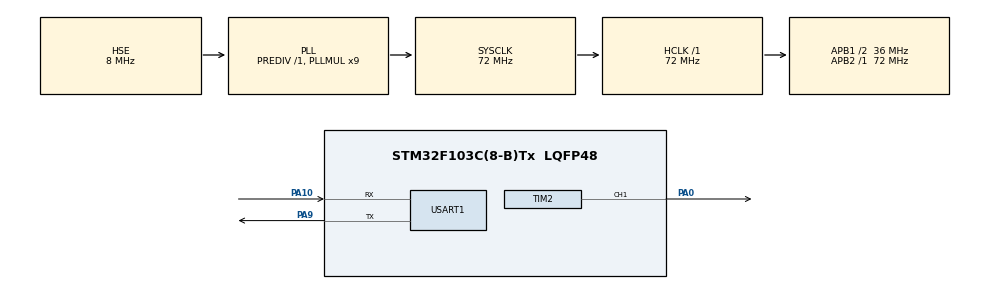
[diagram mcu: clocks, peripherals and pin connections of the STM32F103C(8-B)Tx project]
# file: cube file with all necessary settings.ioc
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Dma.Request0=TIM2_CH1
Dma.TIM2_CH1.0.Direction=DMA_MEMORY_TO_PERIPH
Dma.TIM2_CH1.0.Instance=DMA1_Channel5
Dma.TIM2_CH1.0.MemDataAlignment=DMA_MDATAALIGN_BYTE
Dma.TIM2_CH1.0.MemInc=DMA_MINC_ENABLE
Dma.TIM2_CH1.0.Mode=DMA_CIRCULAR
Dma.TIM2_CH1.0.PeriphDataAlignment=DMA_PDATAALIGN_WORD
Dma.TIM2_CH1.0.PeriphInc=DMA_PINC_DISABLE
Dma.TIM2_CH1.0.Priority=DMA_PRIORITY_HIGH
Mcu.Family=STM32F1
Mcu.Name=STM32F103C(8-B)Tx
Mcu.Package=LQFP48
NVIC.DMA1_Channel5_IRQn=true\:0\:0\:false\:false\:true\:false
NVIC.PriorityGroup=NVIC_PRIORITYGROUP_4
NVIC.TIM2_IRQn=true\:0\:0\:false\:false\:true\:true
PA0-WKUP.GPIO_Speed=GPIO_SPEED_FREQ_HIGH
PA0-WKUP.Signal=S_TIM2_CH1_ETR
PA10.Mode=Asynchronous
PA10.Signal=USART1_RX
PA13.Mode=Serial_Wire
PA13.Signal=SYS_JTMS-SWDIO
PA14.Mode=Serial_Wire
PA14.Signal=SYS_JTCK-SWCLK
PA9.Mode=Asynchronous
PA9.Signal=USART1_TX
PD0-OSC_IN.Mode=HSE-External-Oscillator
PD0-OSC_IN.Signal=RCC_OSC_IN
PD1-OSC_OUT.Mode=HSE-External-Oscillator
PD1-OSC_OUT.Signal=RCC_OSC_OUT
ProjectManager.HeapSize=0x200
ProjectManager.StackSize=0x400
ProjectManager.TargetToolchain=MDK-ARM V5
RCC.AHBFreq_Value=72000000
RCC.APB1CLKDivider=RCC_HCLK_DIV2
RCC.APB1Freq_Value=36000000
RCC.APB1TimFreq_Value=72000000
RCC.APB2Freq_Value=72000000
RCC.APB2TimFreq_Value=72000000
RCC.HCLKFreq_Value=72000000
RCC.PLLMUL=RCC_PLL_MUL9
RCC.PLLSourceVirtual=RCC_PLLSOURCE_HSE
RCC.SYSCLKFreq_VALUE=72000000
RCC.SYSCLKSource=RCC_SYSCLKSOURCE_PLLCLK
RCC.USBFreq_Value=72000000
SH.S_TIM2_CH1_ETR.0=TIM2_CH1,PWM Generation1 CH1
TIM2.AutoReloadPreload=TIM_AUTORELOAD_PRELOAD_DISABLE
TIM2.Channel-PWM\ Generation1\ CH1=TIM_CHANNEL_1
TIM2.Period=0
TIM2.Prescaler=0
TIM2.Pulse-PWM\ Generation1\ CH1=0
USART1.VirtualMode=VM_ASYNC
VP_TIM2_VS_ClockSourceINT.Mode=Internal
board=custom

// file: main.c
/**
  ******************************************************************************
  * @file           : main.c
  * @brief          : Main program body
  ******************************************************************************
  ** This notice applies to any and all portions of this file
  * that are not between comment pairs USER CODE BEGIN and
  * USER CODE END. Other portions of this file, whether
  * inserted by the user or by software development tools
  * are owned by their respective copyright owners.
  *
  * COPYRIGHT(c) 2019 STMicroelectronics
  *
  * Redistribution and use in source and binary forms, with or without modification,
  * are permitted provided that the following conditions are met:
  *   1. Redistributions of source code must retain the above copyright notice,
  *      this list of conditions and the following disclaimer.
  *   2. Redistributions in binary form must reproduce the above copyright notice,
  *      this list of conditions and the following disclaimer in the documentation
  *      and/or other materials provided with the distribution.
  *   3. Neither the name of STMicroelectronics nor the names of its contributors
  *      may be used to endorse or promote products derived from this software
  *      without specific prior written permission.
  *
  * THIS SOFTWARE IS PROVIDED BY THE COPYRIGHT HOLDERS AND CONTRIBUTORS "AS IS"
  * AND ANY EXPRESS OR IMPLIED WARRANTIES, INCLUDING, BUT NOT LIMITED TO, THE
  * IMPLIED WARRANTIES OF MERCHANTABILITY AND FITNESS FOR A PARTICULAR PURPOSE ARE
  * DISCLAIMED. IN NO EVENT SHALL THE COPYRIGHT HOLDER OR CONTRIBUTORS BE LIABLE
  * FOR ANY DIRECT, INDIRECT, INCIDENTAL, SPECIAL, EXEMPLARY, OR CONSEQUENTIAL
  * DAMAGES (INCLUDING, BUT NOT LIMITED TO, PROCUREMENT OF SUBSTITUTE GOODS OR
  * SERVICES; LOSS OF USE, DATA, OR PROFITS; OR BUSINESS INTERRUPTION) HOWEVER
  * CAUSED AND ON ANY THEORY OF LIABILITY, WHETHER IN CONTRACT, STRICT LIABILITY,
  * OR TORT (INCLUDING NEGLIGENCE OR OTHERWISE) ARISING IN ANY WAY OUT OF THE USE
  * OF THIS SOFTWARE, EVEN IF ADVISED OF THE POSSIBILITY OF SUCH DAMAGE.
  *
  ******************************************************************************
  */
#include "main.h"
#include "stm32f1xx_hal.h"

TIM_HandleTypeDef htim2;
DMA_HandleTypeDef hdma_tim2_ch1;
UART_HandleTypeDef huart1;

/* USER CODE BEGIN PV */
/* Private variables ---------------------------------------------------------*/

#include "RGB_library.h"

/* USER CODE END PV */

void SystemClock_Config(void);
static void MX_GPIO_Init(void);
static void MX_DMA_Init(void);
static void MX_TIM2_Init(void);
static void MX_USART1_UART_Init(void);
void HAL_TIM_MspPostInit(TIM_HandleTypeDef *htim);

/* USER CODE BEGIN PFP */
/* Private function prototypes -----------------------------------------------*/

/* USER CODE END PFP */

/* USER CODE BEGIN 0 */

#define WS2812_FREQ											(800000) 			// WS2812 require 800kHz frequency
#define TIMER_CLOCK_FREQ								(72000000)   	// it is depend on APB clk-bus
#define TIMER_PERIOD										(TIMER_CLOCK_FREQ / WS2812_FREQ)
#define LED_NUMBER											3						// number of LEDs we must control
#define LED_DATA_SIZE										(LED_NUMBER * 24)
#define RESET_SLOTS_BEGIN								50	//code reset time
#define RESET_SLOTS_END									50	//code reset time
#define WS2812_LAST_SLOT								1		//set one bit for end of sending pulse
#define LED_BUFFER_SIZE									(RESET_SLOTS_BEGIN + LED_DATA_SIZE + WS2812_LAST_SLOT + RESET_SLOTS_END)
#define WS2812_0											  (TIMER_PERIOD / 3)			// WS2812's zero => high time is one third of the period
#define WS2812_1											  (TIMER_PERIOD * 2 / 3)	// WS2812's one => high time is two thirds of the period
#define WS2812_RESET										 0

/* USER CODE END 0 */

int main(void)
{

  /* MCU Configuration----------------------------------------------------------*/

  /* Reset of all peripherals, Initializes the Flash interface and the Systick. */
  HAL_Init();

  /* Configure the system clock */
  SystemClock_Config();

  /* Initialize all configured peripherals */

	MX_GPIO_Init();
  MX_DMA_Init();
  MX_TIM2_Init();
  MX_USART1_UART_Init();

  /* USER CODE BEGIN 2 */

//	uint32_t pdata[73]={60,60,60,60,60,60,60,60,30,30,30,30,30,30,30,30,30,30,30,30,30,30,30,30,
//						30,30,30,30,30,30,30,30,60,60,60,60,60,60,60,60,30,30,30,30,30,30,30,30,
//						30,30,30,30,30,30,30,30,30,30,30,30,30,30,30,30,60,60,60,60,60,60,60,60,0};

//	HAL_TIM_PWM_Start_DMA(&htim2,TIM_CHANNEL_1,(uint32_t *)pdata,73);

//	HAL_UART_Transmit(&huart1,(uint8_t *)LEDbuffer,LED_BUFFER_SIZE,100);

//	setLEDcolor(0,0x01,0x11,0xf0);
//	setLEDcolor(1,0x00,0xff,0xff);
//	setLEDcolor(2,0x00,0x00,0xff);

	setWHOLEcolor(0xff,0x00,0x00);

	HAL_UART_Transmit(&huart1,(uint8_t *)LEDbuffer,LED_BUFFER_SIZE,100);
  HAL_TIM_PWM_Start_DMA(&htim2, TIM_CHANNEL_1, (uint32_t *) LEDbuffer,LED_BUFFER_SIZE);

  /* USER CODE END 2 */

  /* Infinite loop */
  while (1)
  {

	}

}

void SystemClock_Config(void)
{

  RCC_OscInitTypeDef RCC_OscInitStruct;
  RCC_ClkInitTypeDef RCC_ClkInitStruct;

    /**Initializes the CPU, AHB and APB busses clocks
    */
  RCC_OscInitStruct.OscillatorType = RCC_OSCILLATORTYPE_HSE;
  RCC_OscInitStruct.HSEState = RCC_HSE_ON;
  RCC_OscInitStruct.HSEPredivValue = RCC_HSE_PREDIV_DIV1;
  RCC_OscInitStruct.HSIState = RCC_HSI_ON;
  RCC_OscInitStruct.PLL.PLLState = RCC_PLL_ON;
  RCC_OscInitStruct.PLL.PLLSource = RCC_PLLSOURCE_HSE;
  RCC_OscInitStruct.PLL.PLLMUL = RCC_PLL_MUL9;
  if (HAL_RCC_OscConfig(&RCC_OscInitStruct) != HAL_OK)
  {
    _Error_Handler(__FILE__, __LINE__);
  }

    /**Initializes the CPU, AHB and APB busses clocks
    */
  RCC_ClkInitStruct.ClockType = RCC_CLOCKTYPE_HCLK|RCC_CLOCKTYPE_SYSCLK
                              |RCC_CLOCKTYPE_PCLK1|RCC_CLOCKTYPE_PCLK2;
  RCC_ClkInitStruct.SYSCLKSource = RCC_SYSCLKSOURCE_PLLCLK;
  RCC_ClkInitStruct.AHBCLKDivider = RCC_SYSCLK_DIV1;
  RCC_ClkInitStruct.APB1CLKDivider = RCC_HCLK_DIV2;
  RCC_ClkInitStruct.APB2CLKDivider = RCC_HCLK_DIV1;

  if (HAL_RCC_ClockConfig(&RCC_ClkInitStruct, FLASH_LATENCY_2) != HAL_OK)
  {
    _Error_Handler(__FILE__, __LINE__);
  }

    /**Configure the Systick interrupt time
    */
  HAL_SYSTICK_Config(HAL_RCC_GetHCLKFreq()/1000);

    /**Configure the Systick
    */
  HAL_SYSTICK_CLKSourceConfig(SYSTICK_CLKSOURCE_HCLK);

  /* SysTick_IRQn interrupt configuration */
  HAL_NVIC_SetPriority(SysTick_IRQn, 0, 0);
}

/* TIM2 init function */
static void MX_TIM2_Init(void)
{

  TIM_ClockConfigTypeDef sClockSourceConfig;
  TIM_MasterConfigTypeDef sMasterConfig;
  TIM_OC_InitTypeDef sConfigOC;

  htim2.Instance = TIMx;
  htim2.Init.Prescaler = (uint32_t)((SystemCoreClock / TIMER_CLOCK_FREQ) - 1);
  htim2.Init.CounterMode = TIM_COUNTERMODE_UP;
  htim2.Init.Period = TIMER_PERIOD - 1;
  htim2.Init.ClockDivision = TIM_CLOCKDIVISION_DIV1;
	htim2.Init.RepetitionCounter = LED_BUFFER_SIZE + 1;
	htim2.Init.AutoReloadPreload = TIM_AUTORELOAD_PRELOAD_DISABLE;
  if (HAL_TIM_Base_Init(&htim2) != HAL_OK)
  {
    _Error_Handler(__FILE__, __LINE__);
  }

  sClockSourceConfig.ClockSource = TIM_CLOCKSOURCE_INTERNAL;
  if (HAL_TIM_ConfigClockSource(&htim2, &sClockSourceConfig) != HAL_OK)
  {
    _Error_Handler(__FILE__, __LINE__);
  }

  if (HAL_TIM_PWM_Init(&htim2) != HAL_OK)
  {
    _Error_Handler(__FILE__, __LINE__);
  }

  sMasterConfig.MasterOutputTrigger = TIM_TRGO_RESET;
  sMasterConfig.MasterSlaveMode = TIM_MASTERSLAVEMODE_DISABLE;
  if (HAL_TIMEx_MasterConfigSynchronization(&htim2, &sMasterConfig) != HAL_OK)
  {
    _Error_Handler(__FILE__, __LINE__);
  }

  sConfigOC.OCMode = TIM_OCMODE_PWM1;
  sConfigOC.Pulse = 0;
  sConfigOC.OCPolarity = TIM_OCPOLARITY_HIGH;
  sConfigOC.OCFastMode = TIM_OCFAST_DISABLE;
	sConfigOC.OCIdleState = TIM_OCIDLESTATE_RESET;
  if (HAL_TIM_PWM_ConfigChannel(&htim2, &sConfigOC, TIM_CHANNEL_1) != HAL_OK)
  {
    _Error_Handler(__FILE__, __LINE__);
  }

  HAL_TIM_MspPostInit(&htim2);

}

/* USART1 init function */
static void MX_USART1_UART_Init(void)
{

  huart1.Instance = USART1;
  huart1.Init.BaudRate = 115200;
  huart1.Init.WordLength = UART_WORDLENGTH_8B;
  huart1.Init.StopBits = UART_STOPBITS_1;
  huart1.Init.Parity = UART_PARITY_NONE;
  huart1.Init.Mode = UART_MODE_TX_RX;
  huart1.Init.HwFlowCtl = UART_HWCONTROL_NONE;
  huart1.Init.OverSampling = UART_OVERSAMPLING_16;
  if (HAL_UART_Init(&huart1) != HAL_OK)
  {
    _Error_Handler(__FILE__, __LINE__);
  }

}

static void MX_DMA_Init(void)
{
  /* DMA controller clock enable */
  __HAL_RCC_DMA1_CLK_ENABLE();

  /* DMA interrupt init */
  /* DMA1_Channel5_IRQn interrupt configuration */
  HAL_NVIC_SetPriority(DMA1_Channel5_IRQn, 0, 0);
  HAL_NVIC_EnableIRQ(DMA1_Channel5_IRQn);

}

/** Configure pins as
        * Analog
        * Input
        * Output
        * EVENT_OUT
        * EXTI
*/
static void MX_GPIO_Init(void)
{

  /* GPIO Ports Clock Enable */
  __HAL_RCC_GPIOD_CLK_ENABLE();
  __HAL_RCC_GPIOA_CLK_ENABLE();

}

void _Error_Handler(char *file, int line)
{
  while(1)
  {
  }
}

/************************ (C) COPYRIGHT STMicroelectronics *****END OF FILE****/
